VERSION ""

NS_ :

BS_:

BU_: IMU_139 IMU_138 IMU_137 IMU_128 Encoders

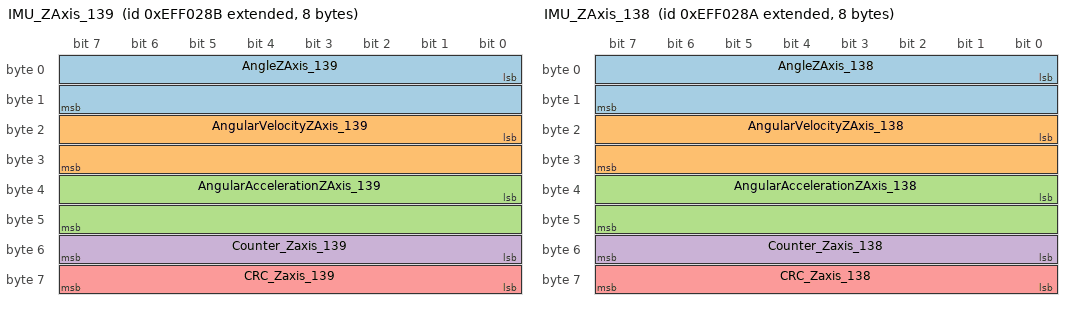
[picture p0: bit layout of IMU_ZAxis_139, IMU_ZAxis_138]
BO_ 2399077003 IMU_ZAxis_139: 8 IMU_139
 SG_ AngleZAxis_139 : 0|16@1+ (0.007813,0) [0|512.024955] "" Vector__XXX
 SG_ AngularVelocityZAxis_139 : 16|16@1+ (0.007813,-250) [-250|262.024955] "" Vector__XXX
 SG_ AngularAccelerationZAxis_139 : 32|16@1+ (0.03125,-1000) [-1000|1047.96875] "" Vector__XXX
 SG_ Counter_Zaxis_139 : 48|8@1+ (1,0) [0|255] "" Vector__XXX
 SG_ CRC_Zaxis_139 : 56|8@1+ (1,0) [0|255] "" Vector__XXX

BO_ 2399077002 IMU_ZAxis_138: 8 IMU_138
 SG_ AngleZAxis_138 : 0|16@1+ (0.007813,0) [0|512.024955] "" Vector__XXX
 SG_ AngularVelocityZAxis_138 : 16|16@1+ (0.007813,-250) [-250|262.024955] "" Vector__XXX
 SG_ AngularAccelerationZAxis_138 : 32|16@1+ (0.03125,-1000) [-1000|1047.96875] "" Vector__XXX
 SG_ Counter_Zaxis_138 : 48|8@1+ (1,0) [0|255] "" Vector__XXX
 SG_ CRC_Zaxis_138 : 56|8@1+ (1,0) [0|255] "" Vector__XXX

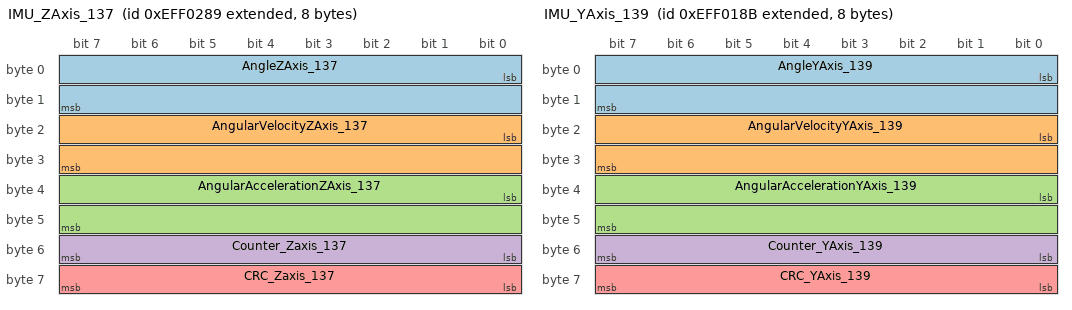
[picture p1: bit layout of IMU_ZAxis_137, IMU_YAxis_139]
BO_ 2399077001 IMU_ZAxis_137: 8 IMU_137
 SG_ AngleZAxis_137 : 0|16@1+ (0.007813,0) [0|512.024955] "" Vector__XXX
 SG_ AngularVelocityZAxis_137 : 16|16@1+ (0.007813,-250) [-250|262.024955] "" Vector__XXX
 SG_ AngularAccelerationZAxis_137 : 32|16@1+ (0.03125,-1000) [-1000|1047.96875] "" Vector__XXX
 SG_ Counter_Zaxis_137 : 48|8@1+ (1,0) [0|255] "" Vector__XXX
 SG_ CRC_Zaxis_137 : 56|8@1+ (1,0) [0|255] "" Vector__XXX

BO_ 2399076747 IMU_YAxis_139: 8 IMU_139
 SG_ AngleYAxis_139 : 0|16@1+ (0.007813,0) [0|512.024955] "" Vector__XXX
 SG_ AngularVelocityYAxis_139 : 16|16@1+ (0.007813,-250) [-250|262.024955] "" Vector__XXX
 SG_ AngularAccelerationYAxis_139 : 32|16@1+ (0.03125,-1000) [-1000|1047.96875] "" Vector__XXX
 SG_ Counter_YAxis_139 : 48|8@1+ (1,0) [0|255] "" Vector__XXX
 SG_ CRC_YAxis_139 : 56|8@1+ (1,0) [0|255] "" Vector__XXX

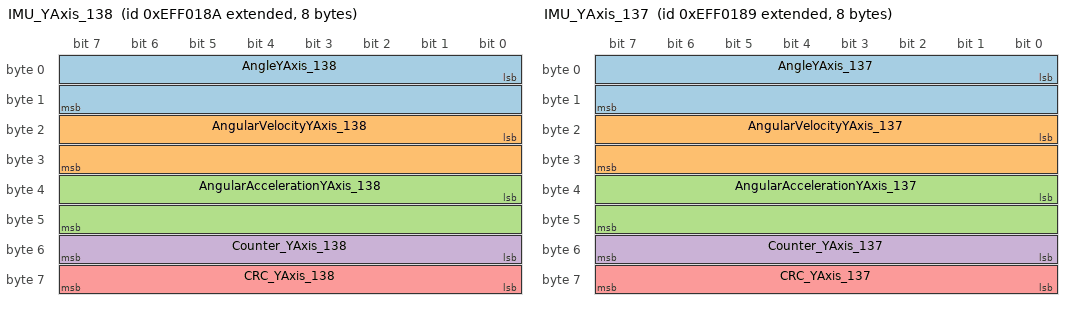
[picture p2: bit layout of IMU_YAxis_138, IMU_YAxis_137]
BO_ 2399076746 IMU_YAxis_138: 8 IMU_138
 SG_ AngleYAxis_138 : 0|16@1+ (0.007813,0) [0|512.024955] "" Vector__XXX
 SG_ AngularVelocityYAxis_138 : 16|16@1+ (0.007813,-250) [-250|262.024955] "" Vector__XXX
 SG_ AngularAccelerationYAxis_138 : 32|16@1+ (0.03125,-1000) [-1000|1047.96875] "" Vector__XXX
 SG_ Counter_YAxis_138 : 48|8@1+ (1,0) [0|255] "" Vector__XXX
 SG_ CRC_YAxis_138 : 56|8@1+ (1,0) [0|255] "" Vector__XXX

BO_ 2399076745 IMU_YAxis_137: 8 IMU_137
 SG_ AngleYAxis_137 : 0|16@1+ (0.007813,0) [0|512.024955] "" Vector__XXX
 SG_ AngularVelocityYAxis_137 : 16|16@1+ (0.007813,-250) [-250|262.024955] "" Vector__XXX
 SG_ AngularAccelerationYAxis_137 : 32|16@1+ (0.03125,-1000) [-1000|1047.96875] "" Vector__XXX
 SG_ Counter_YAxis_137 : 48|8@1+ (1,0) [0|255] "" Vector__XXX
 SG_ CRC_YAxis_137 : 56|8@1+ (1,0) [0|255] "" Vector__XXX

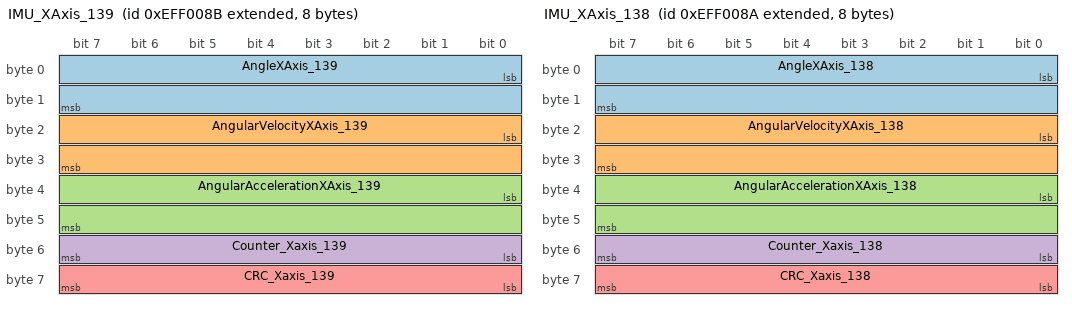
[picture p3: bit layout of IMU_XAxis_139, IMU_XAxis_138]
BO_ 2399076491 IMU_XAxis_139: 8 IMU_139
 SG_ AngleXAxis_139 : 0|16@1+ (0.007813,0) [0|512.024955] "" Vector__XXX
 SG_ AngularVelocityXAxis_139 : 16|16@1+ (0.007813,-250) [-250|262.024955] "" Vector__XXX
 SG_ AngularAccelerationXAxis_139 : 32|16@1+ (0.03125,-1000) [-1000|1047.96875] "" Vector__XXX
 SG_ Counter_Xaxis_139 : 48|8@1+ (1,0) [0|255] "" Vector__XXX
 SG_ CRC_Xaxis_139 : 56|8@1+ (1,0) [0|255] "" Vector__XXX

BO_ 2399076490 IMU_XAxis_138: 8 IMU_138
 SG_ AngleXAxis_138 : 0|16@1+ (0.007813,0) [0|512.024955] "" Vector__XXX
 SG_ AngularVelocityXAxis_138 : 16|16@1+ (0.007813,-250) [-250|262.024955] "" Vector__XXX
 SG_ AngularAccelerationXAxis_138 : 32|16@1+ (0.03125,-1000) [-1000|1047.96875] "" Vector__XXX
 SG_ Counter_Xaxis_138 : 48|8@1+ (1,0) [0|255] "" Vector__XXX
 SG_ CRC_Xaxis_138 : 56|8@1+ (1,0) [0|255] "" Vector__XXX

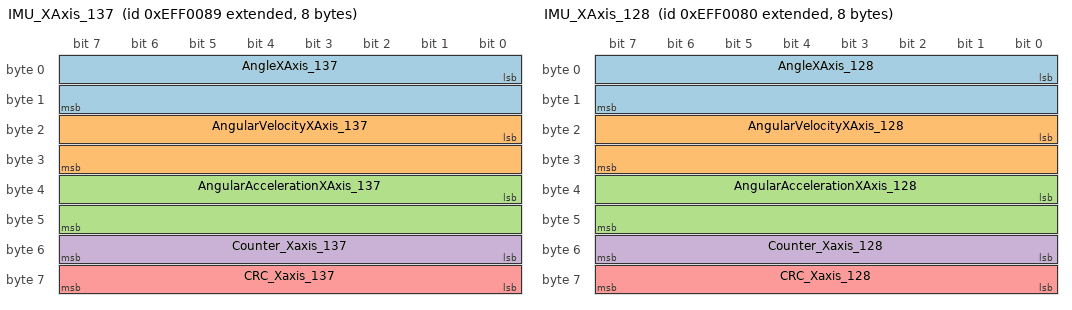
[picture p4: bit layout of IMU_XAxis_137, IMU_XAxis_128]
BO_ 2399076489 IMU_XAxis_137: 8 IMU_137
 SG_ AngleXAxis_137 : 0|16@1+ (0.007813,0) [0|512.024955] "" Vector__XXX
 SG_ AngularVelocityXAxis_137 : 16|16@1+ (0.007813,-250) [-250|262.024955] "" Vector__XXX
 SG_ AngularAccelerationXAxis_137 : 32|16@1+ (0.03125,-1000) [-1000|1047.96875] "" Vector__XXX
 SG_ Counter_Xaxis_137 : 48|8@1+ (1,0) [0|255] "" Vector__XXX
 SG_ CRC_Xaxis_137 : 56|8@1+ (1,0) [0|255] "" Vector__XXX

BO_ 2399076480 IMU_XAxis_128: 8 IMU_128
 SG_ AngleXAxis_128 : 0|16@1+ (0.007813,0) [0|512.024955] "" Vector__XXX
 SG_ AngularVelocityXAxis_128 : 16|16@1+ (0.007813,-250) [-250|262.024955] "" Vector__XXX
 SG_ AngularAccelerationXAxis_128 : 32|16@1+ (0.03125,-1000) [-1000|1047.96875] "" Vector__XXX
 SG_ Counter_Xaxis_128 : 48|8@1+ (1,0) [0|255] "" Vector__XXX
 SG_ CRC_Xaxis_128 : 56|8@1+ (1,0) [0|255] "" Vector__XXX

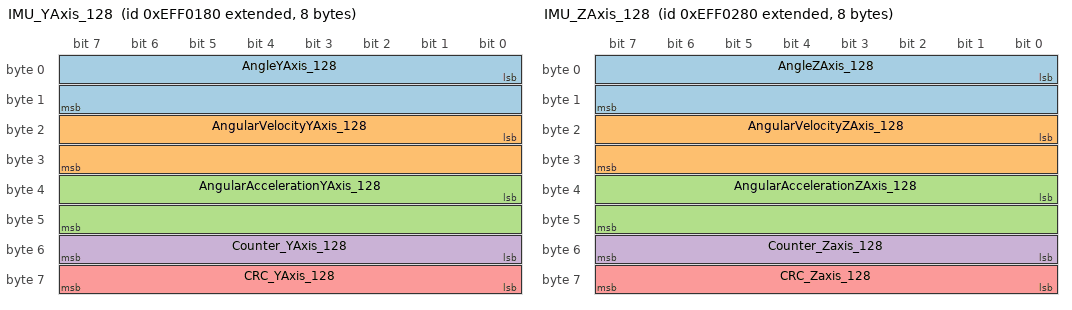
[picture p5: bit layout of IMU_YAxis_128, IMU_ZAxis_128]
BO_ 2399076736 IMU_YAxis_128: 8 IMU_128
 SG_ AngleYAxis_128 : 0|16@1+ (0.007813,0) [0|512.024955] "" Vector__XXX
 SG_ AngularVelocityYAxis_128 : 16|16@1+ (0.007813,-250) [-250|262.024955] "" Vector__XXX
 SG_ AngularAccelerationYAxis_128 : 32|16@1+ (0.03125,-1000) [-1000|1047.96875] "" Vector__XXX
 SG_ Counter_YAxis_128 : 48|8@1+ (1,0) [0|255] "" Vector__XXX
 SG_ CRC_YAxis_128 : 56|8@1+ (1,0) [0|255] "" Vector__XXX

BO_ 2399076992 IMU_ZAxis_128: 8 IMU_128
 SG_ AngleZAxis_128 : 0|16@1+ (0.007813,0) [0|512.024955] "" Vector__XXX
 SG_ AngularVelocityZAxis_128 : 16|16@1+ (0.007813,-250) [-250|262.024955] "" Vector__XXX
 SG_ AngularAccelerationZAxis_128 : 32|16@1+ (0.03125,-1000) [-1000|1047.96875] "" Vector__XXX
 SG_ Counter_Zaxis_128 : 48|8@1+ (1,0) [0|255] "" Vector__XXX
 SG_ CRC_Zaxis_128 : 56|8@1+ (1,0) [0|255] "" Vector__XXX

BO_ 2566892064 Rot_20: 8 Encoders
 SG_ SnsrPos_20 : 0|32@1+ (1,0) [0|4294967295] "" Vector__XXX
 SG_ SnsrRPM_20 : 32|16@1+ (1,0) [0|65535] "" Vector__XXX

BO_ 2566892033 Rot_01: 8 Encoders
 SG_ SnsrPos_01 : 0|32@1+ (1,0) [0|4294967295] "" Vector__XXX
 SG_ SnsrRPM_01 : 32|16@1+ (1,0) [0|65535] "" Vector__XXX

BO_ 2566892083 Rot_33: 8 Encoders
 SG_ SnsrPos_33 : 0|32@1+ (1,0) [0|4294967295] "" Vector__XXX
 SG_ SnsrRPM_33 : 32|16@1+ (1,0) [0|65535] "" Vector__XXX

BA_DEF_ BO_  "GenMsgSendType" ENUM  "Cyclic","NotUsed","NotUsed","NotUsed","NotUsed","NotUsed","NotUsed","IfActive","NoMsgSendType","NotUsed";
BA_DEF_ BO_  "GenMsgCycleTime" INT 0 0;
BA_DEF_ BO_  "VFrameFormat" ENUM  "StandardCAN","ExtendedCAN","reserved","J1939PG";
BA_DEF_ BO_  "SafeCAN1939-76" ENUM  "Normal","SHM","SDM";
BA_DEF_ BO_  "CanTpFcFrameId" HEX 0 2147483647;
BA_DEF_  "BusName" STRING ;
BA_DEF_  "Baudrate" INT 0 1000000;
BA_DEF_  "BusType" STRING ;
BA_DEF_  "Manufacturer" STRING ;
BA_DEF_  "VersionYear" INT 2000 2050;
BA_DEF_  "VersionMonth" INT 1 12;
BA_DEF_  "VersionDay" INT 1 31;
BA_DEF_ SG_  "GenSigStartValue" FLOAT -9.22337203685478E+018 1.84467440737096E+019;
BA_DEF_DEF_  "GenMsgSendType" "Cyclic";
BA_DEF_DEF_  "GenMsgCycleTime" 0;
BA_DEF_DEF_  "VFrameFormat" "ExtendedCAN";
BA_DEF_DEF_  "SafeCAN1939-76" "Normal";
BA_DEF_DEF_  "CanTpFcFrameId" 2147483647;
BA_DEF_DEF_  "BusName" "";
BA_DEF_DEF_  "Baudrate" 0;
BA_DEF_DEF_  "BusType" "";
BA_DEF_DEF_  "Manufacturer" "";
BA_DEF_DEF_  "VersionYear" 2000;
BA_DEF_DEF_  "VersionMonth" 1;
BA_DEF_DEF_  "VersionDay" 1;
BA_DEF_DEF_  "GenSigStartValue" 0;
BA_ "BusName" "Subnet2";
BA_ "BusType" "CAN";
BA_ "Baudrate" 500000;
BA_ "Manufacturer" "VOLVO_CE";
BA_ "VersionYear" 2025;
BA_ "VersionMonth" 2;
BA_ "VersionDay" 3;
BA_ "GenMsgCycleTime" BO_ 2399077003 10;
BA_ "GenMsgCycleTime" BO_ 2399077002 10;
BA_ "GenMsgCycleTime" BO_ 2399077001 10;
BA_ "GenMsgCycleTime" BO_ 2399076747 10;
BA_ "GenMsgCycleTime" BO_ 2399076746 10;
BA_ "GenMsgCycleTime" BO_ 2399076745 10;
BA_ "GenMsgCycleTime" BO_ 2399076491 10;
BA_ "GenMsgCycleTime" BO_ 2399076490 10;
BA_ "GenMsgCycleTime" BO_ 2399076489 10;
BA_ "GenMsgCycleTime" BO_ 2399076480 10;
BA_ "GenMsgCycleTime" BO_ 2399076736 10;
BA_ "GenMsgCycleTime" BO_ 2399076992 10;
BA_ "GenMsgCycleTime" BO_ 2566892064 50;
BA_ "GenMsgCycleTime" BO_ 2566892033 50;
BA_ "GenMsgCycleTime" BO_ 2566892083 50;
BA_ "GenSigStartValue" SG_ 2399076992 AngleZAxis_128 65535;
BA_ "GenSigStartValue" SG_ 2399076992 AngularVelocityZAxis_128 65535;
BA_ "GenSigStartValue" SG_ 2399076992 AngularAccelerationZAxis_128 65535;
BA_ "GenSigStartValue" SG_ 2399076992 Counter_Zaxis_128 255;
BA_ "GenSigStartValue" SG_ 2399076992 CRC_Zaxis_128 255;
BA_ "GenSigStartValue" SG_ 2566892064 SnsrPos_20 4294967295;
BA_ "GenSigStartValue" SG_ 2566892064 SnsrRPM_20 65535;
BA_ "GenSigStartValue" SG_ 2566892033 SnsrPos_01 4294967295;
BA_ "GenSigStartValue" SG_ 2566892033 SnsrRPM_01 65535;
BA_ "GenSigStartValue" SG_ 2566892083 SnsrPos_33 4294967295;
BA_ "GenSigStartValue" SG_ 2566892083 SnsrRPM_33 65535;
